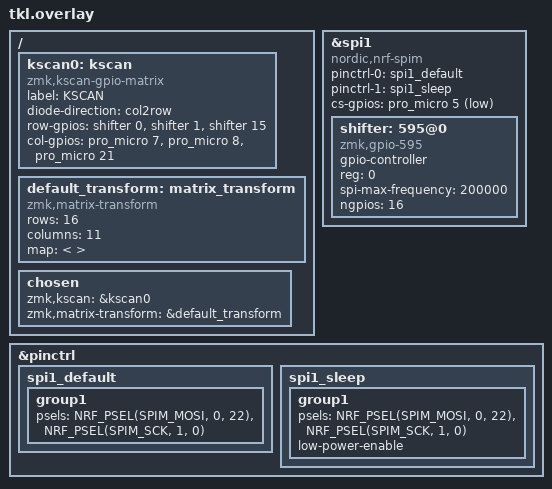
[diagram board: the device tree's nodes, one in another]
#include <behaviors.dtsi>
#include <dt-bindings/zmk/matrix_transform.h>
#include <dt-bindings/zmk/keys.h>

// 1. Сначала на верхнем уровне переопределяем конфигурацию SPI
&spi1 {
    compatible = "nordic,nrf-spim";
    status = "okay";
    pinctrl-0 = <&spi1_default>;
    pinctrl-1 = <&spi1_sleep>;
    pinctrl-names = "default", "sleep";
    cs-gpios = <&pro_micro 5 GPIO_ACTIVE_LOW>;
};

// 2. Также на верхнем уровне настраиваем pinctrl
&pinctrl {
    spi1_default: spi1_default {
        group1 {
            psels = <NRF_PSEL(SPIM_MOSI, 0, 22)>,
                    <NRF_PSEL(SPIM_SCK, 1, 0)>;
        };
    };
    spi1_sleep: spi1_sleep {
        group1 {
            psels = <NRF_PSEL(SPIM_MOSI, 0, 22)>,
                    <NRF_PSEL(SPIM_SCK, 1, 0)>;
            low-power-enable;
        };
    };
};

// 3. Добавляем узел 74HC595 на верхнем уровне
&spi1 {
    shifter: 595@0 {
        compatible = "zmk,gpio-595";
        status = "okay";
        gpio-controller;
        #gpio-cells = <2>;
        reg = <0>;
        spi-max-frequency = <200000>;
        ngpios = <16>;
    };
};

// 4. Только новые узлы (kscan0, matrix_transform, chosen) помещаются внутрь /{ }
/ {
    kscan0: kscan {
        compatible = "zmk,kscan-gpio-matrix";
        label = "KSCAN";
        diode-direction = "col2row";

        row-gpios
            = <&shifter 0 GPIO_ACTIVE_HIGH>
            , <&shifter 1 GPIO_ACTIVE_HIGH>
            // ... остальные 14 строк ...
            , <&shifter 15 GPIO_ACTIVE_HIGH>;

        col-gpios
            = <&pro_micro 7  GPIO_ACTIVE_HIGH>
            , <&pro_micro 8  GPIO_ACTIVE_HIGH>
            // ... остальные 9 столбцов ...
            , <&pro_micro 21 GPIO_ACTIVE_HIGH>;
    };

    default_transform: matrix_transform {
        compatible = "zmk,matrix-transform";
        rows = <16>;
        columns = <11>;
        map = <
            // ... ваша таблица RC(...) ...
        >;
    };

    chosen {
        zmk,kscan = &kscan0;
        zmk,matrix-transform = &default_transform;
    };
};
